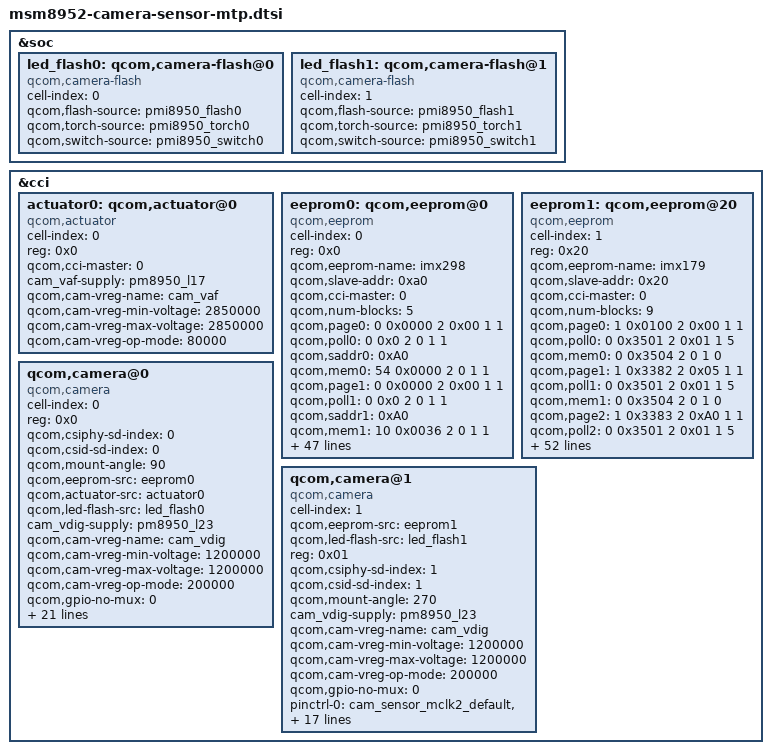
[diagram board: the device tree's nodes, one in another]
/*
 * Copyright (c) 2015, The Linux Foundation. All rights reserved.
 *
 * This program is free software; you can redistribute it and/or modify
 * it under the terms of the GNU General Public License version 2 and
 * only version 2 as published by the Free Software Foundation.
 *
 * This program is distributed in the hope that it will be useful,
 * but WITHOUT ANY WARRANTY; without even the implied warranty of
 * MERCHANTABILITY or FITNESS FOR A PARTICULAR PURPOSE.  See the
 * GNU General Public License for more details.
 */

&soc {
	    led_flash0: qcom,camera-flash@0 {
		cell-index = <0>;
		compatible = "qcom,camera-flash";
		qcom,flash-source = <&pmi8950_flash0 >;
		qcom,torch-source = <&pmi8950_torch0 >;
		qcom,switch-source = <&pmi8950_switch0>;
	};
       led_flash1: qcom,camera-flash@1 {
		cell-index = <1>;
		compatible = "qcom,camera-flash";
		qcom,flash-source = < &pmi8950_flash1>;
		qcom,torch-source = < &pmi8950_torch1>;
		qcom,switch-source = <&pmi8950_switch1>;
	};
		
};


&cci {
	actuator0: qcom,actuator@0 {
		cell-index = <0>;
		reg = <0x0>;
		compatible = "qcom,actuator";
		qcom,cci-master = <0>;
		cam_vaf-supply = <&pm8950_l17>;
		qcom,cam-vreg-name = "cam_vaf";
		qcom,cam-vreg-min-voltage = <2850000>;
		qcom,cam-vreg-max-voltage = <2850000>;
		qcom,cam-vreg-op-mode = <80000>;
	};

	eeprom0: qcom,eeprom@0 {
		cell-index = <0>;
		reg = <0x0>;
		qcom,eeprom-name = "imx298";
		compatible = "qcom,eeprom";
		qcom,slave-addr = <0xa0>;
		qcom,cci-master = <0>;
		qcom,num-blocks = <5>;

		qcom,page0 = <0 0x0000 2 0x00 1 1>;
		qcom,poll0 = <0 0x0 2 0 1 1>;
		qcom,saddr0 =<0xA0>;
		qcom,mem0 = <54 0x0000 2 0 1 1>;
		
		qcom,page1 = <0 0x0000 2 0x00 1 1>;
		qcom,poll1 = <0 0x0 2 0 1 1>;
		qcom,saddr1 =<0xA0>;
		qcom,mem1 = <10 0x0036 2 0 1 1>;
		
		qcom,page2 = <0 0x0000 2 0x00 1 1>;
		qcom,poll2 = <0 0x0 2 0 1 1>;
		qcom,saddr2 =<0xA0>;
		qcom,mem2 = <1770 0x0040 2 0 1 1>;
		
		qcom,page3 = <0 0x0000 2 0x00 1 1>;
		qcom,poll3 = <0 0x0 2 0 1 1>;
		qcom,saddr3 =<0xA0>;
		qcom,mem3 = <254 0x072A 2 0 1 1>;
		
		qcom,page4 = <0 0x0000 2 0x00 1 1>;
		qcom,poll4 = <0 0x0 2 0 1 1>;
		qcom,saddr4 =<0xA0>;
		qcom,mem4 = <98 0x0828 2 0 1 1>;

		
		cam_vaf-supply = <&pm8950_l17>;
		qcom,cam-vreg-name = "cam_vaf";
		qcom,cam-vreg-min-voltage = <2850000>;
		qcom,cam-vreg-max-voltage = <2850000>;
		qcom,cam-vreg-op-mode = <100000>;
		
		pinctrl-names = "cam_default", "cam_suspend";
		pinctrl-0 = <&cam_sensor_mclk0_default	&cam_sensor_rear_default>;
		pinctrl-1 = <&cam_sensor_mclk0_sleep &cam_sensor_rear_sleep>;
		gpios = <&msm_gpio 26 0>,
		        <&msm_gpio 35 0>,
			    <&msm_gpio 36 0>,
			    <&msm_gpio 59 0>,
			    <&msm_gpio 60 0>,
			    <&msm_gpio 128 0>;
		qcom,gpio-standby = <1>;
		qcom,gpio-reset = <2>;
		qcom,gpio-vio = <3>;
		qcom,gpio-vdig = <4>;
		qcom,gpio-vana = <5>;
		qcom,gpio-req-tbl-num = <0 1 2 3 4 5>;
		qcom,gpio-req-tbl-flags = <1 0 0 0 0 0>;
		qcom,gpio-req-tbl-label = "CAMIF_MCLK0",
		       "CAM_STANDBY0",
			   "CAM_RESET0",
			   "CAM_VIO0",
			   "CAM_VDIG0",
			   "CAM_VANA0";
					
		qcom,cam-power-seq-type = "sensor_gpio","sensor_gpio",
		"sensor_gpio","sensor_gpio","sensor_gpio","sensor_gpio",
		"sensor_vreg","sensor_clk","sensor_gpio";
		
		qcom,cam-power-seq-val = "sensor_gpio_reset","sensor_gpio_standby",
		"sensor_gpio_reset","sensor_gpio_vana","sensor_gpio_vdig","sensor_gpio_vio",
		"cam_vaf","sensor_cam_mclk","sensor_gpio_standby";
		
		qcom,cam-power-seq-cfg-val = <0 0 1 1 1 1 1 24000000 1>;
		qcom,cam-power-seq-delay = <1 1 1 0 0 1 1 0 28>;	
		
		status = "ok";
		clocks = <&clock_gcc clk_mclk0_clk_src>,
				<&clock_gcc clk_gcc_camss_mclk0_clk>;
		clock-names = "cam_src_clk", "cam_clk";
	};

	
	eeprom1: qcom,eeprom@20 {
		cell-index = <1>;
		reg = <0x20>;
		qcom,eeprom-name = "imx179";
		compatible = "qcom,eeprom";
		qcom,slave-addr = <0x20>;
		qcom,cci-master = <0>;
		qcom,num-blocks = <9>;

		
		qcom,page0 = <1 0x0100 2 0x00 1 1>;
		qcom,poll0 = <0 0x3501 2 0x01 1 5>;
		qcom,mem0 = <0 0x3504 2 0 1 0>;
		qcom,page1 = <1 0x3382 2 0x05 1 1>;
		qcom,poll1 = <0 0x3501 2 0x01 1 5>;
		qcom,mem1 = <0 0x3504 2 0 1 0>;
		qcom,page2 = <1 0x3383 2 0xA0 1 1>;
		qcom,poll2 = <0 0x3501 2 0x01 1 5>;
		qcom,mem2 = <0 0x3504 2 0 1 0>;
		qcom,page3 = <1 0x3368 2 0x18 1 1>;
		qcom,poll3 = <0 0x3501 2 0x01 1 5>;
		qcom,mem3 = <0 0x3504 2 0 1 0>;
		qcom,page4 = <1 0x3369 2 0x00 1 1>;
		qcom,poll4 = <0 0x3501 2 0x01 1 5>;
		qcom,mem4 = <0 0x3504 2 0 1 0>;
		qcom,page5 = <1 0x3380 2 0x08 1 1>;
		qcom,poll5 = <0 0x3501 2 0x01 1 5>;
		qcom,mem5 = <0 0x3504 2 0 1 0>;
		qcom,page6 = <1 0x3400 2 0x01 1 1>;
		qcom,poll6 = <0 0x3501 2 0x01 1 5>;
		qcom,mem6 = <0 0x3504 2 0 1 0>;
		
		qcom,page7 = <1 0x3402 2 0x00 1 1>;
		qcom,poll7 = <0 0x0 2 0 1 1>;
		qcom,saddr7 =<0x20>;
		qcom,mem7 = <64 0x3404 2 0 1 1>;
		qcom,page8 = <1 0x3402 2 0x01 1 1>;
		qcom,poll8 = <0 0x0 2 0 1 1>;
		qcom,saddr8 =<0x20>;
		qcom,mem8 = <64 0x3404 2 0 1 1>;

		cam_vdig-supply = <&pm8950_l23>;
		qcom,cam-vreg-name = "cam_vdig";
		qcom,cam-vreg-min-voltage = <1200000>;
		qcom,cam-vreg-max-voltage = <1200000>;
		qcom,cam-vreg-op-mode = <200000>;
		
		pinctrl-names = "cam_default", "cam_suspend";
		pinctrl-0 = <&cam_sensor_mclk2_default &cam_sensor_front1_default>;
		pinctrl-1 = <&cam_sensor_mclk2_sleep &cam_sensor_front1_sleep>;
			gpios = <&msm_gpio 28 0>,
			<&msm_gpio 40 0>,
			<&msm_gpio 59 0>,
			<&msm_gpio 129 0>;
		qcom,gpio-reset = <1>;
		qcom,gpio-vio = <2>;
		qcom,gpio-vana = <3>;
		qcom,gpio-req-tbl-num = <0 1 2 3>;
		qcom,gpio-req-tbl-flags = <1 0 0 0>;
		qcom,gpio-req-tbl-label = "CAMIF_MCLK2",
					  "CAM_RESET2",
					  "CAM_VIO2",
					  "CAM_VANA2";
					
		qcom,cam-power-seq-type = "sensor_gpio","sensor_gpio",
		"sensor_gpio","sensor_gpio","sensor_clk",
		"sensor_vreg","sensor_gpio",
		"sensor_gpio","sensor_i2c_mux";
		
		qcom,cam-power-seq-val = "sensor_gpio_vana","sensor_gpio_vana",
		"sensor_gpio_vio","sensor_gpio_vio","sensor_cam_mclk",
		"cam_vdig","sensor_gpio_reset",		
		"sensor_gpio_reset","none";
		
		qcom,cam-power-seq-cfg-val = <0 1 0 1 24000000 0 0 1 0>;
		qcom,cam-power-seq-delay = <0 0 0 0 1 0 1 0 0>;	
		
		status = "ok";
		clocks = <&clock_gcc clk_mclk2_clk_src>,
			<&clock_gcc clk_gcc_camss_mclk2_clk>;
		clock-names = "cam_src_clk", "cam_clk";
	};  

	
	qcom,camera@0 {
		cell-index = <0>;
		compatible = "qcom,camera";
		reg = <0x0>;
		qcom,csiphy-sd-index = <0>;
		qcom,csid-sd-index = <0>;
		qcom,mount-angle = <90>;
		qcom,eeprom-src = <&eeprom0>;
		qcom,actuator-src = <&actuator0>;
		qcom,led-flash-src = <&led_flash0>;

		cam_vdig-supply = <&pm8950_l23>;
		qcom,cam-vreg-name = "cam_vdig";
		qcom,cam-vreg-min-voltage = <1200000>;
		qcom,cam-vreg-max-voltage = <1200000>;
		qcom,cam-vreg-op-mode = <200000>;
		qcom,gpio-no-mux = <0>;
		
		pinctrl-names = "cam_default", "cam_suspend";
		pinctrl-0 = <&cam_sensor_mclk0_default
				&cam_sensor_rear_default>;
		pinctrl-1 = <&cam_sensor_mclk0_sleep &cam_sensor_rear_sleep>;
		gpios = <&msm_gpio 26 0>,
		       <&msm_gpio 35 0>,
			<&msm_gpio 36 0>,
			<&msm_gpio 59 0>,
			<&msm_gpio 60 0>,
			<&msm_gpio 128 0>;
		qcom,gpio-standby = <1>;
		qcom,gpio-reset = <2>;
		qcom,gpio-vio = <3>;
		qcom,gpio-vdig = <4>;
		qcom,gpio-vana = <5>;
		qcom,gpio-req-tbl-num = <0 1 2 3 4 5>;
		qcom,gpio-req-tbl-flags = <1 0 0 0 0 0>;
		qcom,gpio-req-tbl-label = "CAMIF_MCLK0",
		       "CAM_STANDBY0",
			"CAM_RESET0",
			"CAM_VIO0",
			"CAM_VDIG0",
			"CAM_VANA0";
		qcom,sensor-position = <0>;
		qcom,sensor-mode = <0>;
		qcom,cci-master = <0>;
		status = "ok";
		clocks = <&clock_gcc clk_mclk0_clk_src>,
				<&clock_gcc clk_gcc_camss_mclk0_clk>;
		clock-names = "cam_src_clk", "cam_clk";
	};

	qcom,camera@1 {
		cell-index = <1>;
		compatible = "qcom,camera";
		qcom,eeprom-src = <&eeprom1>;
		qcom,led-flash-src = <&led_flash1>;
		reg = <0x01>;
		qcom,csiphy-sd-index = <1>;
		qcom,csid-sd-index = <1>;
		qcom,mount-angle = <270>;
		cam_vdig-supply = <&pm8950_l23>;
		qcom,cam-vreg-name = "cam_vdig";
		qcom,cam-vreg-min-voltage = <1200000>;
		qcom,cam-vreg-max-voltage = <1200000>;
		qcom,cam-vreg-op-mode = <200000>;
		qcom,gpio-no-mux = <0>;
		
		pinctrl-names = "cam_default", "cam_suspend";
		pinctrl-0 = <&cam_sensor_mclk2_default &cam_sensor_front1_default>;
		pinctrl-1 = <&cam_sensor_mclk2_sleep &cam_sensor_front1_sleep>;
		gpios = <&msm_gpio 28 0>,
			<&msm_gpio 40 0>,
			<&msm_gpio 59 0>,
			<&msm_gpio 129 0>;
		qcom,gpio-reset = <1>;
		qcom,gpio-vio = <2>;
		qcom,gpio-vana = <3>;
		qcom,gpio-req-tbl-num = <0 1 2 3>;
		qcom,gpio-req-tbl-flags = <1 0 0 0>;
		qcom,gpio-req-tbl-label = "CAMIF_MCLK2",
					  "CAM_RESET2",
					  "CAM_VIO2",
					  "CAM_VANA2";
		qcom,sensor-position = <1>;
		qcom,sensor-mode = <0>;
		qcom,cci-master = <0>;
		status = "ok";
		clocks = <&clock_gcc clk_mclk2_clk_src>,
			<&clock_gcc clk_gcc_camss_mclk2_clk>;
		clock-names = "cam_src_clk", "cam_clk";
	};

};
